AUTOSAR XML (schema 4-0-3)
standard types defined: Boolean, UInt16, UInt32
package /AUTOSAR_Platform/DataConstrs
  range DC_UInt16: raw 0..65535
package /PATAC/MSM/ComponentTypes
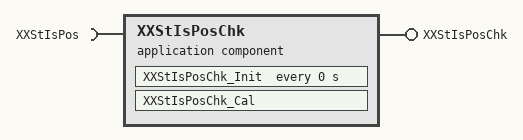
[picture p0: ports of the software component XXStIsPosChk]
  application sw component type XXStIsPosChk
    provide port XXStIsPosChk: server-com-spec{operation=Cal, queue-length=1}, provided-interface=XXStIsPosChk
    require port XXStIsPos: client-com-spec=Get, required-interface=XXStIsPos
    behavior XXStIsPosChk_InternalBehavior
      operation invoked event OIT_XXStIsPosChk_Cal_XXStIsPosChk_Cal: start-on-event=XXStIsPosChk_Cal, operation=XXStIsPosChk.Cal
      timing event XXStIsPosChk_InitEvent: start-on-event=XXStIsPosChk_Init, period=0
      runnable XXStIsPosChk_Cal
        sync call SC_XXStIsPos_Get: operation=XXStIsPos.Get, timeout=0
      runnable XXStIsPosChk_Init
  swc implementation XXStIsPosChk_Implementation: behavior=XXStIsPosChk_InternalBehavior
    code-descriptors:
      code Default: artifact-descriptors=autosar-engineering-object={short-label=Default, category=SWSRC}
package /PATAC/MSM/ModeAdjust/DataType
  impl type TrgtPosCalibArray: category=ARRAY, sw-calibration-access=READ-ONLY, type-emitter=RTE  # 0:pos 1:max 2:min
    element Element: array-size=3, array-size-semantics=FIXED-SIZE, implementation-data-type=UInt16, invalid-value=0
  impl type TrgtPosCalibArray32: category=ARRAY, sw-calibration-access=READ-ONLY, type-emitter=RTE  # 0:pos 1:max 2:min
    element Element: array-size=96, array-size-semantics=FIXED-SIZE, implementation-data-type=UInt16, invalid-value=0
package /PATAC/MSM/ModeAdjust/PortInterface
  client server interface XXStIsPos
    operation Get
      8 x arg, all with server-argument-impl-policy=USE-ARGUMENT-TYPE:
        PosV: type=DataTypes/Boolean, direction=IN
        Pos: type=UInt16, direction=IN
        CalibArray: type=TrgtPosCalibArray, direction=IN
        Delta: type=UInt16, direction=IN
        Tolr: type=UInt16, direction=IN
        IsPos: type=DataTypes/Boolean, direction=OUT
        IsPosZone: type=DataTypes/Boolean, direction=OUT
        IsPosAlready: type=DataTypes/Boolean, direction=OUT
  client server interface XXStIsPosChk
    operation Cal
      13 x arg, all with server-argument-impl-policy=USE-ARGUMENT-TYPE:
        MdCalibArray32: type=TrgtPosCalibArray32, direction=IN
        Pos: type=UInt16, direction=IN
        PosV: type=DataTypes/Boolean, direction=IN
        MovConfig: type=DataTypes/Boolean, direction=IN
        modestate32: type=UInt32, direction=IN
        IsPos: type=UInt32, direction=OUT
        IsPosAlready: type=UInt32, direction=OUT
        IsPosZone: type=UInt32, direction=OUT
        NotMovFlg: type=DataTypes/Boolean, direction=OUT
        StTrgtPos: type=UInt16, direction=OUT
        PosDelta: type=UInt16, direction=IN
        PosTolr: type=UInt16, direction=IN
        StBitMask: type=UInt32, direction=IN
